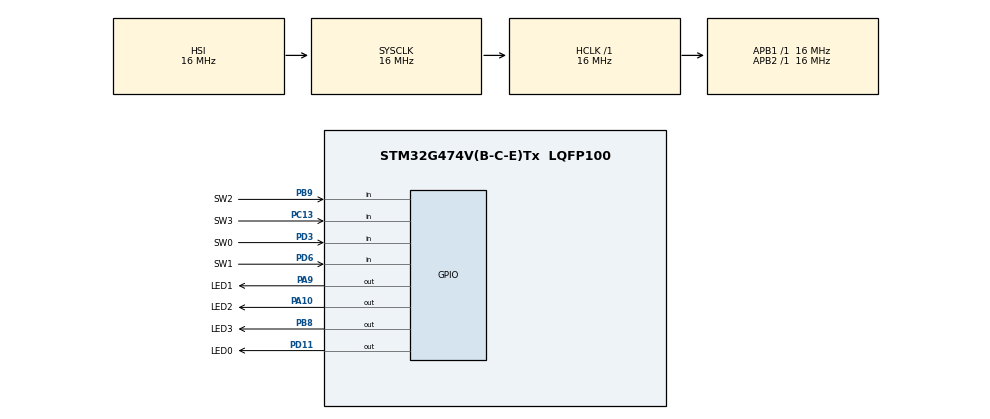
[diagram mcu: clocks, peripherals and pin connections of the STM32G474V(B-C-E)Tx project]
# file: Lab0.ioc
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Mcu.Family=STM32G4
Mcu.Name=STM32G474V(B-C-E)Tx
Mcu.Package=LQFP100
NVIC.PriorityGroup=NVIC_PRIORITYGROUP_4
PA10.GPIO_Label=LED2
PA10.Signal=GPIO_Output
PA13.Mode=Serial_Wire
PA13.Signal=SYS_JTMS-SWDIO
PA14.Mode=Serial_Wire
PA14.Signal=SYS_JTCK-SWCLK
PA9.GPIO_Label=LED1
PA9.Signal=GPIO_Output
PB8-BOOT0.GPIO_Label=LED3
PB8-BOOT0.Signal=GPIO_Output
PB9.GPIO_Label=SW2
PB9.GPIO_PuPd=GPIO_PULLUP
PB9.Signal=GPIO_Input
PC13.GPIO_Label=SW3
PC13.GPIO_PuPd=GPIO_PULLUP
PC13.Signal=GPIO_Input
PD11.GPIO_Label=LED0
PD11.Signal=GPIO_Output
PD3.GPIO_Label=SW0
PD3.GPIO_PuPd=GPIO_PULLUP
PD3.Signal=GPIO_Input
PD6.GPIO_Label=SW1
PD6.GPIO_PuPd=GPIO_PULLUP
PD6.Signal=GPIO_Input
ProjectManager.HeapSize=0x200
ProjectManager.StackSize=0x400
ProjectManager.TargetToolchain=Makefile
RCC.AHBFreq_Value=16000000
RCC.APB1Freq_Value=16000000
RCC.APB1TimFreq_Value=16000000
RCC.APB2Freq_Value=16000000
RCC.APB2TimFreq_Value=16000000
RCC.CortexFreq_Value=16000000
RCC.EXTERNAL_CLOCK_VALUE=12288000
RCC.HCLKFreq_Value=16000000
RCC.HSE_VALUE=8000000
RCC.HSI48_VALUE=48000000
RCC.HSI_VALUE=16000000
RCC.LSE_VALUE=32768
RCC.SYSCLKFreq_VALUE=16000000
RCC.USBFreq_Value=64000000
RCC.VCOOutputFreq_Value=128000000
VP_SYS_VS_DBSignals.Mode=DisableDeadBatterySignals
board=custom

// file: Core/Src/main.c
/* USER CODE BEGIN Header */
/**
  ******************************************************************************
  * @file           : main.c
  * @brief          : Main program body
  ******************************************************************************
  * @attention
  *
  * Copyright (c) 2025 STMicroelectronics.
  * All rights reserved.
  *
  * This software is licensed under terms that can be found in the LICENSE file
  * in the root directory of this software component.
  * If no LICENSE file comes with this software, it is provided AS-IS.
  *
  ******************************************************************************
  */
/* USER CODE END Header */
#include "main.h"

void SystemClock_Config(void);
static void MX_GPIO_Init(void);

int main(void) {

    /* MCU Configuration--------------------------------------------------------*/

    /* Reset of all peripherals, Initializes the Flash interface and the Systick. */
    HAL_Init();

    /* Configure the system clock */
    SystemClock_Config();

    /* Initialize all configured peripherals */
    MX_GPIO_Init();
    /* USER CODE BEGIN 2 */
    // previous button state, current state.
    uint32_t prev = 0, curr = 0;
    /* USER CODE END 2 */

    /* Infinite loop */
    /* USER CODE BEGIN WHILE */
    //
    while (1) {
        curr = HAL_GPIO_ReadPin(SW3_GPIO_Port, SW3_Pin);
        if (prev == GPIO_PIN_SET && curr == GPIO_PIN_RESET) {
            HAL_GPIO_TogglePin(LED0_GPIO_Port, LED0_Pin);
        }
        prev = curr;

        /* Part 2, problem 2, practice of Lab0
        uint16_t buttons_pin[4] = {SW0_Pin, SW1_Pin, SW2_Pin, SW3_Pin};
        GPIO_TypeDef* buttons_port[4] = {SW0_GPIO_Port, SW1_GPIO_Port, SW2_GPIO_Port, SW3_GPIO_Port};
        uint16_t led_pin[4] = {LED0_Pin, LED1_Pin, LED2_Pin, LED3_Pin};
        GPIO_TypeDef* led_port[4] = {LED0_GPIO_Port, LED1_GPIO_Port, LED2_GPIO_Port, LED3_GPIO_Port};
        for (uint32_t i = 0; i < 4; ++i) {
            if (HAL_GPIO_ReadPin(buttons_port[i], buttons_pin[i]) == GPIO_PIN_RESET) {
                HAL_GPIO_WritePin(led_port[i], led_pin[i], GPIO_PIN_SET);
            } else {
                HAL_GPIO_WritePin(led_port[i], led_pin[i], GPIO_PIN_RESET);
            }
        }
        */

        /* Part 1, problem 2, practice of Lab0
        if (HAL_GPIO_ReadPin(SW3_GPIO_Port, SW3_Pin) == GPIO_PIN_RESET) {
            HAL_GPIO_WritePin(LED0_GPIO_Port, LED0_Pin, GPIO_PIN_SET);
        } else {
            HAL_GPIO_WritePin(LED0_GPIO_Port, LED0_Pin, GPIO_PIN_RESET);
        }
        */
        /* USER CODE END WHILE */

    }
}

void SystemClock_Config(void) {
    RCC_OscInitTypeDef RCC_OscInitStruct = {0};
    RCC_ClkInitTypeDef RCC_ClkInitStruct = {0};

    /** Configure the main internal regulator output voltage
    */
    HAL_PWREx_ControlVoltageScaling(PWR_REGULATOR_VOLTAGE_SCALE1);

    /** Initializes the RCC Oscillators according to the specified parameters
    * in the RCC_OscInitTypeDef structure.
    */
    RCC_OscInitStruct.OscillatorType = RCC_OSCILLATORTYPE_HSI;
    RCC_OscInitStruct.HSIState = RCC_HSI_ON;
    RCC_OscInitStruct.HSICalibrationValue = RCC_HSICALIBRATION_DEFAULT;
    RCC_OscInitStruct.PLL.PLLState = RCC_PLL_NONE;
    if (HAL_RCC_OscConfig(&RCC_OscInitStruct) != HAL_OK) {
        Error_Handler();
    }

    /** Initializes the CPU, AHB and APB buses clocks
    */
    RCC_ClkInitStruct.ClockType = RCC_CLOCKTYPE_HCLK | RCC_CLOCKTYPE_SYSCLK
        | RCC_CLOCKTYPE_PCLK1 | RCC_CLOCKTYPE_PCLK2;
    RCC_ClkInitStruct.SYSCLKSource = RCC_SYSCLKSOURCE_HSI;
    RCC_ClkInitStruct.AHBCLKDivider = RCC_SYSCLK_DIV1;
    RCC_ClkInitStruct.APB1CLKDivider = RCC_HCLK_DIV1;
    RCC_ClkInitStruct.APB2CLKDivider = RCC_HCLK_DIV1;

    if (HAL_RCC_ClockConfig(&RCC_ClkInitStruct, FLASH_LATENCY_0) != HAL_OK) {
        Error_Handler();
    }
}

static void MX_GPIO_Init(void) {
    GPIO_InitTypeDef GPIO_InitStruct = {0};

    /* GPIO Ports Clock Enable */
    __HAL_RCC_GPIOC_CLK_ENABLE();
    __HAL_RCC_GPIOD_CLK_ENABLE();
    __HAL_RCC_GPIOA_CLK_ENABLE();
    __HAL_RCC_GPIOB_CLK_ENABLE();

    /*Configure GPIO pin Output Level */
    HAL_GPIO_WritePin(LED0_GPIO_Port, LED0_Pin, GPIO_PIN_RESET);

    /*Configure GPIO pin Output Level */
    HAL_GPIO_WritePin(GPIOA, LED1_Pin | LED2_Pin, GPIO_PIN_RESET);

    /*Configure GPIO pin Output Level */
    HAL_GPIO_WritePin(LED3_GPIO_Port, LED3_Pin, GPIO_PIN_RESET);

    /*Configure GPIO pin : SW3_Pin */
    GPIO_InitStruct.Pin = SW3_Pin;
    GPIO_InitStruct.Mode = GPIO_MODE_INPUT;
    GPIO_InitStruct.Pull = GPIO_PULLUP;
    HAL_GPIO_Init(SW3_GPIO_Port, &GPIO_InitStruct);

    /*Configure GPIO pin : LED0_Pin */
    GPIO_InitStruct.Pin = LED0_Pin;
    GPIO_InitStruct.Mode = GPIO_MODE_OUTPUT_PP;
    GPIO_InitStruct.Pull = GPIO_NOPULL;
    GPIO_InitStruct.Speed = GPIO_SPEED_FREQ_LOW;
    HAL_GPIO_Init(LED0_GPIO_Port, &GPIO_InitStruct);

    /*Configure GPIO pins : LED1_Pin LED2_Pin */
    GPIO_InitStruct.Pin = LED1_Pin | LED2_Pin;
    GPIO_InitStruct.Mode = GPIO_MODE_OUTPUT_PP;
    GPIO_InitStruct.Pull = GPIO_NOPULL;
    GPIO_InitStruct.Speed = GPIO_SPEED_FREQ_LOW;
    HAL_GPIO_Init(GPIOA, &GPIO_InitStruct);

    /*Configure GPIO pins : SW0_Pin SW1_Pin */
    GPIO_InitStruct.Pin = SW0_Pin | SW1_Pin;
    GPIO_InitStruct.Mode = GPIO_MODE_INPUT;
    GPIO_InitStruct.Pull = GPIO_PULLUP;
    HAL_GPIO_Init(GPIOD, &GPIO_InitStruct);

    /*Configure GPIO pin : LED3_Pin */
    GPIO_InitStruct.Pin = LED3_Pin;
    GPIO_InitStruct.Mode = GPIO_MODE_OUTPUT_PP;
    GPIO_InitStruct.Pull = GPIO_NOPULL;
    GPIO_InitStruct.Speed = GPIO_SPEED_FREQ_LOW;
    HAL_GPIO_Init(LED3_GPIO_Port, &GPIO_InitStruct);

    /*Configure GPIO pin : SW2_Pin */
    GPIO_InitStruct.Pin = SW2_Pin;
    GPIO_InitStruct.Mode = GPIO_MODE_INPUT;
    GPIO_InitStruct.Pull = GPIO_PULLUP;
    HAL_GPIO_Init(SW2_GPIO_Port, &GPIO_InitStruct);

}

void Error_Handler(void) {
    __disable_irq();
    while (1) {}
}
